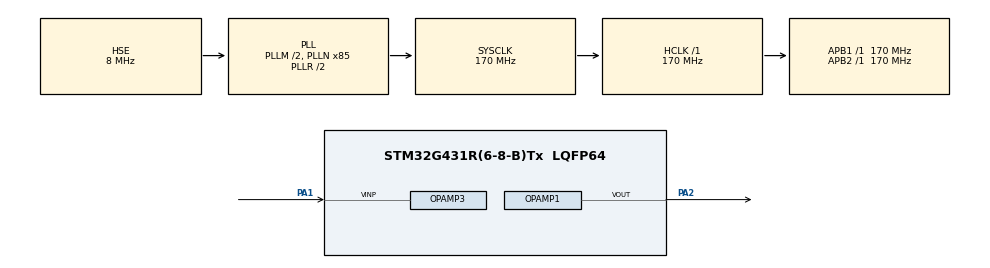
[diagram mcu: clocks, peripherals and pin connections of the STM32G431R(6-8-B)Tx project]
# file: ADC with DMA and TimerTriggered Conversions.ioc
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ADC2.Channel-0\#ChannelRegularConversion=ADC_CHANNEL_VOPAMP3_ADC2
ADC2.DMAContinuousRequests=ENABLE
ADC2.ExternalTrigConv=ADC_EXTERNALTRIG_T6_TRGO
ADC2.NbrOfConversion=1
ADC2.NbrOfConversionFlag=1
ADC2.OffsetNumber-0\#ChannelRegularConversion=ADC_OFFSET_NONE
ADC2.Rank-0\#ChannelRegularConversion=1
ADC2.SamplingTime-0\#ChannelRegularConversion=ADC_SAMPLETIME_6CYCLES_5
DAC3.DAC_SampleAndHold-DAC_OUT1_Int=DAC_SAMPLEANDHOLD_DISABLE
DAC3.DAC_Trigger_OUT1-DAC_OUT1_Int=DAC_TRIGGER_T6_TRGO
Dma.ADC2.0.Direction=DMA_PERIPH_TO_MEMORY
Dma.ADC2.0.EventEnable=DISABLE
Dma.ADC2.0.Instance=DMA1_Channel1
Dma.ADC2.0.MemDataAlignment=DMA_MDATAALIGN_WORD
Dma.ADC2.0.MemInc=DMA_MINC_ENABLE
Dma.ADC2.0.Mode=DMA_CIRCULAR
Dma.ADC2.0.PeriphDataAlignment=DMA_PDATAALIGN_WORD
Dma.ADC2.0.PeriphInc=DMA_PINC_DISABLE
Dma.ADC2.0.Polarity=HAL_DMAMUX_REQ_GEN_RISING
Dma.ADC2.0.Priority=DMA_PRIORITY_LOW
Dma.ADC2.0.RequestNumber=1
Dma.ADC2.0.SignalID=NONE
Dma.ADC2.0.SyncEnable=DISABLE
Dma.ADC2.0.SyncPolarity=HAL_DMAMUX_SYNC_NO_EVENT
Dma.ADC2.0.SyncRequestNumber=1
Dma.ADC2.0.SyncSignalID=NONE
Dma.DAC3_CH1.1.Direction=DMA_MEMORY_TO_PERIPH
Dma.DAC3_CH1.1.EventEnable=DISABLE
Dma.DAC3_CH1.1.Instance=DMA1_Channel2
Dma.DAC3_CH1.1.MemDataAlignment=DMA_MDATAALIGN_WORD
Dma.DAC3_CH1.1.MemInc=DMA_MINC_ENABLE
Dma.DAC3_CH1.1.Mode=DMA_CIRCULAR
Dma.DAC3_CH1.1.PeriphDataAlignment=DMA_PDATAALIGN_WORD
Dma.DAC3_CH1.1.PeriphInc=DMA_PINC_DISABLE
Dma.DAC3_CH1.1.Polarity=HAL_DMAMUX_REQ_GEN_RISING
Dma.DAC3_CH1.1.Priority=DMA_PRIORITY_LOW
Dma.DAC3_CH1.1.RequestNumber=1
Dma.DAC3_CH1.1.SignalID=NONE
Dma.DAC3_CH1.1.SyncEnable=DISABLE
Dma.DAC3_CH1.1.SyncPolarity=HAL_DMAMUX_SYNC_NO_EVENT
Dma.DAC3_CH1.1.SyncRequestNumber=1
Dma.DAC3_CH1.1.SyncSignalID=NONE
Dma.Request0=ADC2
Dma.Request1=DAC3_CH1
Mcu.Family=STM32G4
Mcu.Name=STM32G431R(6-8-B)Tx
Mcu.Package=LQFP64
NVIC.ADC1_2_IRQn=true\:0\:0\:false\:false\:true\:true\:true\:true
NVIC.DMA1_Channel1_IRQn=true\:0\:0\:false\:false\:true\:false\:true\:true
NVIC.DMA1_Channel2_IRQn=true\:0\:0\:false\:false\:true\:false\:true\:true
NVIC.PriorityGroup=NVIC_PRIORITYGROUP_4
OPAMP1.PowerMode=OPAMP_POWERMODE_HIGHSPEED
OPAMP3.PowerMode=OPAMP_POWERMODE_HIGHSPEED
PA1.Mode=Follower_Internally_Connected
PA1.Signal=OPAMP3_VINP
PA13.Mode=Serial_Wire
PA13.Signal=SYS_JTMS-SWDIO
PA14.Mode=Serial_Wire
PA14.Signal=SYS_JTCK-SWCLK
PA2.Mode=Follower-DAC_OUT2-INP
PA2.Signal=OPAMP1_VOUT
PF0-OSC_IN.Mode=HSE-External-Oscillator
PF0-OSC_IN.Signal=RCC_OSC_IN
PF1-OSC_OUT.Mode=HSE-External-Oscillator
PF1-OSC_OUT.Signal=RCC_OSC_OUT
ProjectManager.HeapSize=0x200
ProjectManager.StackSize=0x400
ProjectManager.TargetToolchain=STM32CubeIDE
RCC.ADC12Freq_Value=170000000
RCC.AHBFreq_Value=170000000
RCC.APB1Freq_Value=170000000
RCC.APB1TimFreq_Value=170000000
RCC.APB2Freq_Value=170000000
RCC.APB2TimFreq_Value=170000000
RCC.CortexFreq_Value=170000000
RCC.EXTERNAL_CLOCK_VALUE=12288000
RCC.HCLKFreq_Value=170000000
RCC.HSE_VALUE=8000000
RCC.HSI48_VALUE=48000000
RCC.HSI_VALUE=16000000
RCC.LSE_VALUE=32768
RCC.PLLM=RCC_PLLM_DIV2
RCC.PLLN=85
RCC.PLLSourceVirtual=RCC_PLLSOURCE_HSE
RCC.SYSCLKFreq_VALUE=170000000
RCC.SYSCLKSource=RCC_SYSCLKSOURCE_PLLCLK
RCC.USBFreq_Value=170000000
RCC.VCOOutputFreq_Value=340000000
SYS.VoltageScaling=SYSCFG_VREFBUF_VOLTAGE_SCALE0
TIM6.AutoReloadPreload=TIM_AUTORELOAD_PRELOAD_ENABLE
TIM6.PeriodNoDither=5-1
TIM6.Prescaler=17-1
TIM6.TIM_MasterOutputTrigger=TIM_TRGO_UPDATE
VP_ADC2_OPAMP_INTERNAL3.Mode=IN-OPAMP3
VP_DAC3_VS_DACI1.Mode=DAC_OUT1_Int
VP_SYS_VS_DBSignals.Mode=DisableDeadBatterySignals
VP_TIM6_VS_ClockSourceINT.Mode=Enable_Timer
VREF+.Mode=InternalMode
VREF+.Signal=VREFBUF_OUT
board=custom

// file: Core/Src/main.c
/* USER CODE BEGIN Header */
/**
  ******************************************************************************
  * @file           : main.c
  * @brief          : Main program body
  ******************************************************************************
  * @attention
  *
  * Copyright (c) 2024 STMicroelectronics.
  * All rights reserved.
  *
  * This software is licensed under terms that can be found in the LICENSE file
  * in the root directory of this software component.
  * If no LICENSE file comes with this software, it is provided AS-IS.
  *
  ******************************************************************************
  */
/* USER CODE END Header */
#include "main.h"

/* USER CODE BEGIN Includes */
#define BUFFER_SIZE 1000
#define BUFFER_SIZE_HALF BUFFER_SIZE/2

/* USER CODE END Includes */

ADC_HandleTypeDef hadc2;
DMA_HandleTypeDef hdma_adc2;

DAC_HandleTypeDef hdac3;
DMA_HandleTypeDef hdma_dac3_ch1;

OPAMP_HandleTypeDef hopamp1;
OPAMP_HandleTypeDef hopamp3;

TIM_HandleTypeDef htim6;

/* USER CODE BEGIN PV */

uint32_t ADC_BUFFER[BUFFER_SIZE];
uint32_t DAC_BUFFER[BUFFER_SIZE];

uint32_t ADC_VALUE;

/* USER CODE END PV */

void SystemClock_Config(void);
static void MX_GPIO_Init(void);
static void MX_DMA_Init(void);
static void MX_ADC2_Init(void);
static void MX_TIM6_Init(void);
static void MX_DAC3_Init(void);
static void MX_OPAMP1_Init(void);
static void MX_OPAMP3_Init(void);

int main(void)
{

  /* MCU Configuration--------------------------------------------------------*/

  /* Reset of all peripherals, Initializes the Flash interface and the Systick. */
  HAL_Init();

  /* Configure the system clock */
  SystemClock_Config();

  /* Initialize all configured peripherals */
  MX_GPIO_Init();
  MX_DMA_Init();
  MX_ADC2_Init();
  MX_TIM6_Init();
  MX_DAC3_Init();
  MX_OPAMP1_Init();
  MX_OPAMP3_Init();
  /* USER CODE BEGIN 2 */

HAL_OPAMP_Start(&hopamp1);
HAL_OPAMP_Start(&hopamp3);

HAL_ADC_Start_DMA(&hadc2, ADC_BUFFER, BUFFER_SIZE);
//HAL_DAC_Start_DMA(&hdac3, DAC_CHANNEL_1, DAC_BUFFER, BUFFER_SIZE, DAC_ALIGN_12B_R);
HAL_DAC_Start_DMA(&hdac3, DAC_CHANNEL_1, DAC_BUFFER, BUFFER_SIZE, DAC_ALIGN_12B_R);
HAL_TIM_Base_Start(&htim6);

  /* USER CODE END 2 */

  /* Infinite loop */
  while (1)
  {

  }
}

void SystemClock_Config(void)
{
  RCC_OscInitTypeDef RCC_OscInitStruct = {0};
  RCC_ClkInitTypeDef RCC_ClkInitStruct = {0};

  /** Configure the main internal regulator output voltage
  */
  HAL_PWREx_ControlVoltageScaling(PWR_REGULATOR_VOLTAGE_SCALE1_BOOST);

  /** Initializes the RCC Oscillators according to the specified parameters
  * in the RCC_OscInitTypeDef structure.
  */
  RCC_OscInitStruct.OscillatorType = RCC_OSCILLATORTYPE_HSE;
  RCC_OscInitStruct.HSEState = RCC_HSE_ON;
  RCC_OscInitStruct.PLL.PLLState = RCC_PLL_ON;
  RCC_OscInitStruct.PLL.PLLSource = RCC_PLLSOURCE_HSE;
  RCC_OscInitStruct.PLL.PLLM = RCC_PLLM_DIV2;
  RCC_OscInitStruct.PLL.PLLN = 85;
  RCC_OscInitStruct.PLL.PLLP = RCC_PLLP_DIV2;
  RCC_OscInitStruct.PLL.PLLQ = RCC_PLLQ_DIV2;
  RCC_OscInitStruct.PLL.PLLR = RCC_PLLR_DIV2;
  if (HAL_RCC_OscConfig(&RCC_OscInitStruct) != HAL_OK)
  {
    Error_Handler();
  }

  /** Initializes the CPU, AHB and APB buses clocks
  */
  RCC_ClkInitStruct.ClockType = RCC_CLOCKTYPE_HCLK|RCC_CLOCKTYPE_SYSCLK
                              |RCC_CLOCKTYPE_PCLK1|RCC_CLOCKTYPE_PCLK2;
  RCC_ClkInitStruct.SYSCLKSource = RCC_SYSCLKSOURCE_PLLCLK;
  RCC_ClkInitStruct.AHBCLKDivider = RCC_SYSCLK_DIV1;
  RCC_ClkInitStruct.APB1CLKDivider = RCC_HCLK_DIV1;
  RCC_ClkInitStruct.APB2CLKDivider = RCC_HCLK_DIV1;

  if (HAL_RCC_ClockConfig(&RCC_ClkInitStruct, FLASH_LATENCY_4) != HAL_OK)
  {
    Error_Handler();
  }
}

static void MX_ADC2_Init(void)
{

  ADC_ChannelConfTypeDef sConfig = {0};

  /** Common config
  */
  hadc2.Instance = ADC2;
  hadc2.Init.ClockPrescaler = ADC_CLOCK_SYNC_PCLK_DIV4;
  hadc2.Init.Resolution = ADC_RESOLUTION_12B;
  hadc2.Init.DataAlign = ADC_DATAALIGN_RIGHT;
  hadc2.Init.GainCompensation = 0;
  hadc2.Init.ScanConvMode = ADC_SCAN_DISABLE;
  hadc2.Init.EOCSelection = ADC_EOC_SINGLE_CONV;
  hadc2.Init.LowPowerAutoWait = DISABLE;
  hadc2.Init.ContinuousConvMode = DISABLE;
  hadc2.Init.NbrOfConversion = 1;
  hadc2.Init.DiscontinuousConvMode = DISABLE;
  hadc2.Init.ExternalTrigConv = ADC_EXTERNALTRIG_T6_TRGO;
  hadc2.Init.ExternalTrigConvEdge = ADC_EXTERNALTRIGCONVEDGE_RISING;
  hadc2.Init.DMAContinuousRequests = ENABLE;
  hadc2.Init.Overrun = ADC_OVR_DATA_PRESERVED;
  hadc2.Init.OversamplingMode = DISABLE;
  if (HAL_ADC_Init(&hadc2) != HAL_OK)
  {
    Error_Handler();
  }

  /** Configure Regular Channel
  */
  sConfig.Channel = ADC_CHANNEL_VOPAMP3_ADC2;
  sConfig.Rank = ADC_REGULAR_RANK_1;
  sConfig.SamplingTime = ADC_SAMPLETIME_6CYCLES_5;
  sConfig.SingleDiff = ADC_SINGLE_ENDED;
  sConfig.OffsetNumber = ADC_OFFSET_NONE;
  sConfig.Offset = 0;
  if (HAL_ADC_ConfigChannel(&hadc2, &sConfig) != HAL_OK)
  {
    Error_Handler();
  }

}

static void MX_DAC3_Init(void)
{

  DAC_ChannelConfTypeDef sConfig = {0};

  /** DAC Initialization
  */
  hdac3.Instance = DAC3;
  if (HAL_DAC_Init(&hdac3) != HAL_OK)
  {
    Error_Handler();
  }

  /** DAC channel OUT1 config
  */
  sConfig.DAC_HighFrequency = DAC_HIGH_FREQUENCY_INTERFACE_MODE_AUTOMATIC;
  sConfig.DAC_DMADoubleDataMode = DISABLE;
  sConfig.DAC_SignedFormat = DISABLE;
  sConfig.DAC_SampleAndHold = DAC_SAMPLEANDHOLD_DISABLE;
  sConfig.DAC_Trigger = DAC_TRIGGER_T6_TRGO;
  sConfig.DAC_Trigger2 = DAC_TRIGGER_NONE;
  sConfig.DAC_OutputBuffer = DAC_OUTPUTBUFFER_DISABLE;
  sConfig.DAC_ConnectOnChipPeripheral = DAC_CHIPCONNECT_INTERNAL;
  sConfig.DAC_UserTrimming = DAC_TRIMMING_FACTORY;
  if (HAL_DAC_ConfigChannel(&hdac3, &sConfig, DAC_CHANNEL_1) != HAL_OK)
  {
    Error_Handler();
  }

}

static void MX_OPAMP1_Init(void)
{

  hopamp1.Instance = OPAMP1;
  hopamp1.Init.PowerMode = OPAMP_POWERMODE_HIGHSPEED;
  hopamp1.Init.Mode = OPAMP_FOLLOWER_MODE;
  hopamp1.Init.NonInvertingInput = OPAMP_NONINVERTINGINPUT_DAC;
  hopamp1.Init.InternalOutput = DISABLE;
  hopamp1.Init.TimerControlledMuxmode = OPAMP_TIMERCONTROLLEDMUXMODE_DISABLE;
  hopamp1.Init.UserTrimming = OPAMP_TRIMMING_FACTORY;
  if (HAL_OPAMP_Init(&hopamp1) != HAL_OK)
  {
    Error_Handler();
  }

}

static void MX_OPAMP3_Init(void)
{

  hopamp3.Instance = OPAMP3;
  hopamp3.Init.PowerMode = OPAMP_POWERMODE_HIGHSPEED;
  hopamp3.Init.Mode = OPAMP_FOLLOWER_MODE;
  hopamp3.Init.NonInvertingInput = OPAMP_NONINVERTINGINPUT_IO2;
  hopamp3.Init.InternalOutput = ENABLE;
  hopamp3.Init.TimerControlledMuxmode = OPAMP_TIMERCONTROLLEDMUXMODE_DISABLE;
  hopamp3.Init.UserTrimming = OPAMP_TRIMMING_FACTORY;
  if (HAL_OPAMP_Init(&hopamp3) != HAL_OK)
  {
    Error_Handler();
  }

}

static void MX_TIM6_Init(void)
{

  TIM_MasterConfigTypeDef sMasterConfig = {0};

  htim6.Instance = TIM6;
  htim6.Init.Prescaler = 17-1;
  htim6.Init.CounterMode = TIM_COUNTERMODE_UP;
  htim6.Init.Period = 4;
  htim6.Init.AutoReloadPreload = TIM_AUTORELOAD_PRELOAD_ENABLE;
  if (HAL_TIM_Base_Init(&htim6) != HAL_OK)
  {
    Error_Handler();
  }
  sMasterConfig.MasterOutputTrigger = TIM_TRGO_UPDATE;
  sMasterConfig.MasterSlaveMode = TIM_MASTERSLAVEMODE_DISABLE;
  if (HAL_TIMEx_MasterConfigSynchronization(&htim6, &sMasterConfig) != HAL_OK)
  {
    Error_Handler();
  }

}

static void MX_DMA_Init(void)
{

  /* DMA controller clock enable */
  __HAL_RCC_DMAMUX1_CLK_ENABLE();
  __HAL_RCC_DMA1_CLK_ENABLE();

  /* DMA interrupt init */
  /* DMA1_Channel1_IRQn interrupt configuration */
  HAL_NVIC_SetPriority(DMA1_Channel1_IRQn, 0, 0);
  HAL_NVIC_EnableIRQ(DMA1_Channel1_IRQn);
  /* DMA1_Channel2_IRQn interrupt configuration */
  HAL_NVIC_SetPriority(DMA1_Channel2_IRQn, 0, 0);
  HAL_NVIC_EnableIRQ(DMA1_Channel2_IRQn);

}

static void MX_GPIO_Init(void)
{

  /* GPIO Ports Clock Enable */
  __HAL_RCC_GPIOF_CLK_ENABLE();
  __HAL_RCC_GPIOA_CLK_ENABLE();

}

/* USER CODE BEGIN 4 */

 void HAL_ADC_ConvCpltCallback(ADC_HandleTypeDef *hadc)
{
  /* Prevent unused argument(s) compilation warning */
//	 ADC_VALUE = ADC_BUFFER[1];

	for (size_t i = 0; i < BUFFER_SIZE_HALF; i++) {
		DAC_BUFFER[i] = ADC_BUFFER[i];

	}

  /* NOTE : This function should not be modified. When the callback is needed,
            function HAL_ADC_ConvCpltCallback must be implemented in the user file.
   */
}

/**
  * @brief  Conversion DMA half-transfer callback in non-blocking mode.
  * @param hadc ADC handle
  * @retval None
  */
 void HAL_ADC_ConvHalfCpltCallback(ADC_HandleTypeDef *hadc)
{
  /* Prevent unused argument(s) compilation warning */

		for (size_t i = BUFFER_SIZE_HALF; i < BUFFER_SIZE; i++) {
			DAC_BUFFER[i] = ADC_BUFFER[i];

		}

  /* NOTE : This function should not be modified. When the callback is needed,
            function HAL_ADC_ConvHalfCpltCallback must be implemented in the user file.
  */
}

/* USER CODE END 4 */

void Error_Handler(void)
{
  __disable_irq();
  while (1)
  {
  }
}
